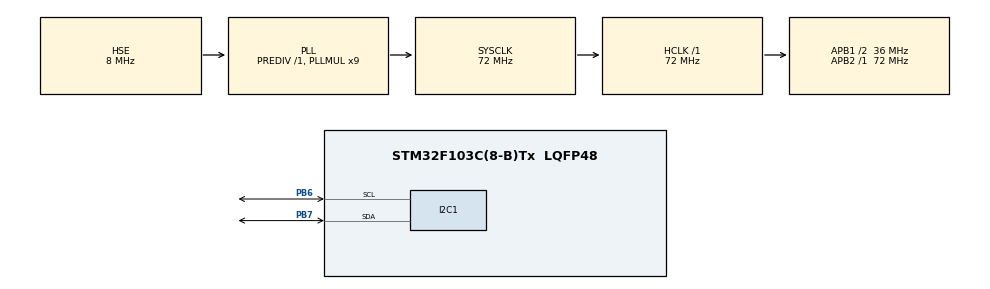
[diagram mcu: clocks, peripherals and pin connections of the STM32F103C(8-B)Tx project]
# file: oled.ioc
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FREERTOS.Tasks01=defaultTask,24,128,StartDefaultTask,Default,NULL,Dynamic,NULL,NULL;Oled_Task,8,128,Oled_Func,Default,NULL,Dynamic,NULL,NULL
FREERTOS.configUSE_NEWLIB_REENTRANT=1
I2C1.AddressingMode=I2C_ADDRESSINGMODE_7BIT
I2C1.I2C_Mode=I2C_Fast
Mcu.Family=STM32F1
Mcu.Name=STM32F103C(8-B)Tx
Mcu.Package=LQFP48
NVIC.PriorityGroup=NVIC_PRIORITYGROUP_4
PB6.Mode=I2C
PB6.Signal=I2C1_SCL
PB7.Mode=I2C
PB7.Signal=I2C1_SDA
PD0-OSC_IN.Mode=HSE-External-Oscillator
PD0-OSC_IN.Signal=RCC_OSC_IN
PD1-OSC_OUT.Mode=HSE-External-Oscillator
PD1-OSC_OUT.Signal=RCC_OSC_OUT
ProjectManager.HeapSize=0x200
ProjectManager.StackSize=0x400
ProjectManager.TargetToolchain=STM32CubeIDE
RCC.AHBFreq_Value=72000000
RCC.APB1CLKDivider=RCC_HCLK_DIV2
RCC.APB1Freq_Value=36000000
RCC.APB1TimFreq_Value=72000000
RCC.APB2Freq_Value=72000000
RCC.APB2TimFreq_Value=72000000
RCC.HCLKFreq_Value=72000000
RCC.PLLMUL=RCC_PLL_MUL9
RCC.PLLSourceVirtual=RCC_PLLSOURCE_HSE
RCC.SYSCLKFreq_VALUE=72000000
RCC.SYSCLKSource=RCC_SYSCLKSOURCE_PLLCLK
RCC.USBFreq_Value=72000000
VP_FREERTOS_VS_CMSIS_V2.Mode=CMSIS_V2
board=custom

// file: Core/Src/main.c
/* USER CODE BEGIN Header */
/**
  ******************************************************************************
  * @file           : main.c
  * @brief          : Main program body
  ******************************************************************************
  * @attention
  *
  * Copyright (c) 2023 STMicroelectronics.
  * All rights reserved.
  *
  * This software is licensed under terms that can be found in the LICENSE file
  * in the root directory of this software component.
  * If no LICENSE file comes with this software, it is provided AS-IS.
  *
  ******************************************************************************
  */
/* USER CODE END Header */
#include "main.h"
#include "cmsis_os.h"
#include "i2c.h"
#include "gpio.h"

void SystemClock_Config(void);
void MX_FREERTOS_Init(void);

int main(void)
{

  /* MCU Configuration--------------------------------------------------------*/

  /* Reset of all peripherals, Initializes the Flash interface and the Systick. */
  HAL_Init();

  /* Configure the system clock */
  SystemClock_Config();

  /* Initialize all configured peripherals */
  MX_GPIO_Init();
  MX_I2C1_Init();
  /* USER CODE BEGIN 2 */
  uint8_t check = SSD1306_Init ();
  /* USER CODE END 2 */

  /* Init scheduler */
  osKernelInitialize();  /* Call init function for freertos objects (in freertos.c) */
  MX_FREERTOS_Init();

  /* Start scheduler */
  osKernelStart();

  /* We should never get here as control is now taken by the scheduler */
  /* Infinite loop */
  while (1)
  {

    /* USER CODE BEGIN 3 */
	  //sprintf(buff,"Hello World");

  }
  /* USER CODE END 3 */
}

void SystemClock_Config(void)
{
  RCC_OscInitTypeDef RCC_OscInitStruct = {0};
  RCC_ClkInitTypeDef RCC_ClkInitStruct = {0};

  /** Initializes the RCC Oscillators according to the specified parameters
  * in the RCC_OscInitTypeDef structure.
  */
  RCC_OscInitStruct.OscillatorType = RCC_OSCILLATORTYPE_HSE;
  RCC_OscInitStruct.HSEState = RCC_HSE_ON;
  RCC_OscInitStruct.HSEPredivValue = RCC_HSE_PREDIV_DIV1;
  RCC_OscInitStruct.HSIState = RCC_HSI_ON;
  RCC_OscInitStruct.PLL.PLLState = RCC_PLL_ON;
  RCC_OscInitStruct.PLL.PLLSource = RCC_PLLSOURCE_HSE;
  RCC_OscInitStruct.PLL.PLLMUL = RCC_PLL_MUL9;
  if (HAL_RCC_OscConfig(&RCC_OscInitStruct) != HAL_OK)
  {
    Error_Handler();
  }

  /** Initializes the CPU, AHB and APB buses clocks
  */
  RCC_ClkInitStruct.ClockType = RCC_CLOCKTYPE_HCLK|RCC_CLOCKTYPE_SYSCLK
                              |RCC_CLOCKTYPE_PCLK1|RCC_CLOCKTYPE_PCLK2;
  RCC_ClkInitStruct.SYSCLKSource = RCC_SYSCLKSOURCE_PLLCLK;
  RCC_ClkInitStruct.AHBCLKDivider = RCC_SYSCLK_DIV1;
  RCC_ClkInitStruct.APB1CLKDivider = RCC_HCLK_DIV2;
  RCC_ClkInitStruct.APB2CLKDivider = RCC_HCLK_DIV1;

  if (HAL_RCC_ClockConfig(&RCC_ClkInitStruct, FLASH_LATENCY_2) != HAL_OK)
  {
    Error_Handler();
  }
}

void Error_Handler(void)
{
  __disable_irq();
  while (1)
  {
  }
}

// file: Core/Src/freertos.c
/* USER CODE BEGIN Header */
/**
  ******************************************************************************
  * File Name          : freertos.c
  * Description        : Code for freertos applications
  ******************************************************************************
  * @attention
  *
  * Copyright (c) 2023 STMicroelectronics.
  * All rights reserved.
  *
  * This software is licensed under terms that can be found in the LICENSE file
  * in the root directory of this software component.
  * If no LICENSE file comes with this software, it is provided AS-IS.
  *
  ******************************************************************************
  */
/* USER CODE END Header */

#include "FreeRTOS.h"
#include "task.h"
#include "main.h"
#include "cmsis_os.h"

/* USER CODE BEGIN Includes */
#include "stdio.h"
#include "ssd1306.h"
/* USER CODE END Includes */

/* USER CODE BEGIN Variables */
char buff[20];
/* USER CODE END Variables */
/* Definitions for defaultTask */
osThreadId_t defaultTaskHandle;
const osThreadAttr_t defaultTask_attributes = {
  .name = "defaultTask",
  .stack_size = 128 * 4,
  .priority = (osPriority_t) osPriorityNormal,
};
/* Definitions for Oled_Task */
osThreadId_t Oled_TaskHandle;
const osThreadAttr_t Oled_Task_attributes = {
  .name = "Oled_Task",
  .stack_size = 128 * 4,
  .priority = (osPriority_t) osPriorityLow,
};

void StartDefaultTask(void *argument);
void Oled_Func(void *argument);

void MX_FREERTOS_Init(void); /* (MISRA C 2004 rule 8.1) */

void MX_FREERTOS_Init(void) {

  /* Create the thread(s) */
  /* creation of defaultTask */
  defaultTaskHandle = osThreadNew(StartDefaultTask, NULL, &defaultTask_attributes);

  /* creation of Oled_Task */
  Oled_TaskHandle = osThreadNew(Oled_Func, NULL, &Oled_Task_attributes);

}

void StartDefaultTask(void *argument)
{
  for(;;)
  {
    osDelay(1);
  }
}

void Oled_Func(void *argument)
{
  /* USER CODE BEGIN Oled_Func */
  /* Infinite loop */
  for(;;)
  {
	  sprintf(buff,"hello world");
	  		SSD1306_Fill (0);  // fill the display with black color
	  		SSD1306_GotoXY (0,0);  // goto 10, 10
	  		SSD1306_Puts (buff, &Font_11x18, 0);
	  		SSD1306_UpdateScreen();

    osDelay(1);
  }
  /* USER CODE END Oled_Func */
}
